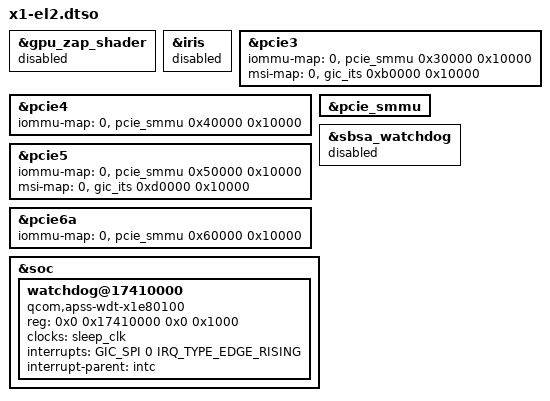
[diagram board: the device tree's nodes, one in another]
// SPDX-License-Identifier: BSD-3-Clause

/*
 * x1 specific modifications required to boot in EL2.
 */

/dts-v1/;
/plugin/;

#include <dt-bindings/interrupt-controller/arm-gic.h>

/* We can't and don't need to use zap shader in EL2 as linux can zap the gpu on it's own. */
&gpu_zap_shader {
	status = "disabled";
};

&iris {
	/* TODO: Add video-firmware iommus to start IRIS from EL2 */
	status = "disabled";
};

/*
 * When running under Gunyah, this IOMMU is controlled by the firmware,
 * however when we take ownership of it in EL2, we need to configure
 * it properly to use PCIe.
 *
 * Additionally, it seems like ITS emulation in Gunyah is broken so we
 * can't use MSI on some PCIe controllers in EL1. But we can add them
 * here for EL2.
 */
&pcie3 {
	iommu-map = <0 &pcie_smmu 0x30000 0x10000>;
	msi-map = <0 &gic_its 0xb0000 0x10000>;
};

&pcie4 {
	iommu-map = <0 &pcie_smmu 0x40000 0x10000>;
};

&pcie5 {
	iommu-map = <0 &pcie_smmu 0x50000 0x10000>;
	msi-map = <0 &gic_its 0xd0000 0x10000>;
};

&pcie6a {
	iommu-map = <0 &pcie_smmu 0x60000 0x10000>;
};

&pcie_smmu {
	status = "okay";
};

/*
 * The "SBSA watchdog" is implemented in software in Gunyah
 * and can't be used when running in EL2.
 */
&sbsa_watchdog {
	status = "disabled";
};

&soc {
	#address-cells = <2>;
	#size-cells = <2>;

	/* The APSS watchdog is only accessible in EL2 */
	watchdog@17410000 {
		compatible = "qcom,apss-wdt-x1e80100", "qcom,kpss-wdt";
		reg = <0x0 0x17410000 0x0 0x1000>;
		clocks = <&sleep_clk>;
		interrupts = <GIC_SPI 0 IRQ_TYPE_EDGE_RISING>;
		interrupt-parent = <&intc>;
	};
};
